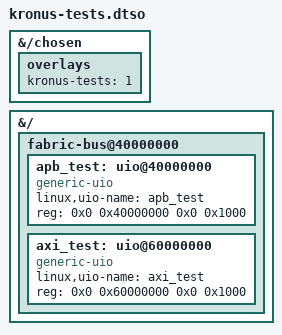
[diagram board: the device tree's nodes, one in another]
/dts-v1/;
/plugin/;

&{/chosen} {
	overlays {
		kronus-tests = "1";
	};
};

&{/} {
	fabric-bus@40000000 {
		apb_test: uio@40000000 {
			compatible = "generic-uio";
			linux,uio-name = "apb_test";
			reg = <0x0 0x40000000 0x0 0x1000>;
			status = "okay";
		};

		axi_test: uio@60000000 {
			compatible = "generic-uio";
			linux,uio-name = "axi_test";
			reg = <0x0 0x60000000 0x0 0x1000>;
			status = "okay";
		};
	};
};
